# OPA1_1.0 register map
Vendor: Texas Instruments
Peripheral module from a debugger description file (folder mspm0g1x0x_g3x0x).
Registers are 32-bit, read-write, no defined reset value unless marked. A register's access mark holds for its fields unless they carry their own. Offsets are as the file gives them; lines under a group give offsets from that group; [hi:lo] are bit positions; {n}, {i} and the like mark numbered series; 'fields as' and 'values as' point back to an identical list; <NAME> marks a mode.

## OPA1
0x800 OPA1_GPRCM group
  0x00 OPA1_PWREN — Power enable
    [0] ENABLE — Enable the power
      0=DISABLE (Disable Power); 1=ENABLE (Enable Power)
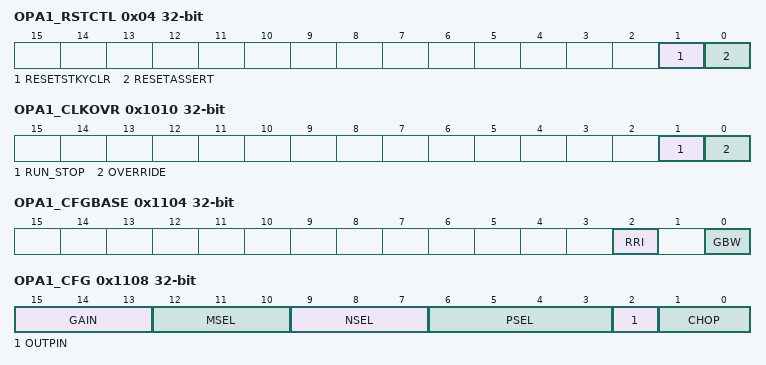
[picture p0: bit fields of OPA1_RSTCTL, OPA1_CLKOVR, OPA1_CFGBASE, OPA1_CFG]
  0x04 OPA1_RSTCTL — Reset Control
    [1] RESETSTKYCLR — Clear the RESETSTKY bit in the STAT register
      0=NOP (Writing 0 has no effect); 1=CLR (Clear reset sticky bit)
    [0] RESETASSERT — Assert reset to the peripheral
      0=NOP (Writing 0 has no effect); 1=ASSERT (Assert reset)
  0x14 OPA1_GPRCM_STAT ro — Status Register
    [16] RESETSTKY — This bit indicates, if the peripheral was reset, since this bit was cleared by RESETSTKYCLR in the RSTCTL register
      0=NORES (The peripheral has not been reset since this bit was last cleared by RESETSTKYCLR in the RSTCTL register); 1=RESET (The peripheral was reset since the last bit clear)
0x1010 OPA1_CLKOVR — Clock Override
  [1] RUN_STOP — If [OVERRIDE] is enabled, this register is used to manually control the peripheral's clock request to the system
    0=RUN (Run/ungate functional clock); 1=STOP (Stop/gate functional clock)
  [0] OVERRIDE — Unlocks the functionality of [RUN_STOP] to override the automatic peripheral clock request
    0=DISABLED (Override disabled); 1=ENABLED (Override enabled)
0x101C OPA1_PWRCTL — Power Control
  [0] AUTO_OFF — When set the peripheral will remove its local IP request for enable so that it can be disabled if no other entities in the system are requesting it to be enabled.
    0=DISABLE (Disable automatic power off function); 1=ENABLE (Enable automatic power off function)
0x1100 OPA1_CTL — Control Register
  [0] ENABLE — OAxn Enable.
    0=OFF (OAxn OFF); 1=ON (OAxn ON)
0x1104 OPA1_CFGBASE — Configuration Base Register
  [2] RRI — Rail-to-rail input enable. Can only be modified when STAT.BUSY=0
    0=OFF (Rail-to-rail input disable.); 1=ON (Rail-to-rail input enable.)
  [0] GBW — Select gain bandwidth which affects current as well the gain bandwidth. The lower gain bandwidth has lower current. See device specific datasheet for values. Can only be modified when STAT.BUSY=0.
    0=LOWGAIN (Low gain bandwidth. See device specific datasheet for gain bandwidth.); 1=HIGHGAIN (High gain bandwidth. See device specific datasheet for gain bandwidth.)
0x1108 OPA1_CFG — Configuration Register
  [15:13] GAIN — Gain setting. Refer to TRM for enumeration information.
    0=MINIMUM (Minmum gain value); 7=MAXIMUM (Maximum gain value.)
  [12:10] MSEL — MSEL Mux selection. Please refer to the device specific datasheet for exact channels available.
    0=NC (no connect); 1=EXTNPIN1 (external pin OAn-1); 2=VSS; 3=DAC12OUT (DAC12 Output); 4=OANM1RTOP (OA[n-1]Rtop)
  [9:7] NSEL — Negative OA input selection. Please refer to the device specific datasheet for exact channels available.
    0=NC (no connect); 1=EXTPIN0 (external pin OAn-0); 2=EXTPIN1 (external pin OAn-1); 3=OANP1RBOT (OA[n+1]Rbot); 4=OANRTAP; 5=OANRTOP; 6=SPARE (Spare input)
  [6:3] PSEL — Positive OA input selection. Please refer to the device specific datasheet for exact channels available.
    0=NC (No connect); 1=EXTPIN0 (external pin OA+0); 2=EXTPIN1 (external pin OAn+1); 3=DAC12OUT; 4=DAC8OUT; 5=VREF (VREF Channel); 6=OANM1RTOP (OA[n-1]Rtop); 7=GPAMP_OUT_INT (GPAMP_OUT_INT Input); 8=VSS (Internal Grouund Connection)
  [2] OUTPIN — Enable output pin
    0=DISABLED (Output pin disabled); 1=ENABLED (Output pin enabled)
  [1:0] CHOP — Chopping enable.
    0=OFF (Chopping disable.); 1=ON (Standard chopping enable.); 2=AVGON (Chop with post average on. Requires output to be connect to ADC in average mode.)
0x1118 OPA1_STAT ro — Status Register
  [0] RDY — OA ready status.
    0=FALSE (OAxn is not ready.); 1=TRUE (OAxn is ready.)
